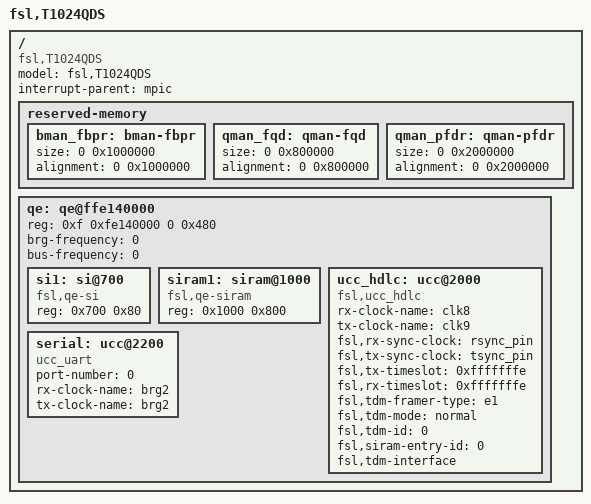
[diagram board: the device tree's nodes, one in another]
/*
 * T1024 QDS Device Tree Source
 *
 * Copyright 2014 Freescale Semiconductor Inc.
 *
 * Redistribution and use in source and binary forms, with or without
 * modification, are permitted provided that the following conditions are met:
 *     * Redistributions of source code must retain the above copyright
 *	 notice, this list of conditions and the following disclaimer.
 *     * Redistributions in binary form must reproduce the above copyright
 *	 notice, this list of conditions and the following disclaimer in the
 *	 documentation and/or other materials provided with the distribution.
 *     * Neither the name of Freescale Semiconductor nor the
 *	 names of its contributors may be used to endorse or promote products
 *	 derived from this software without specific prior written permission.
 *
 *
 * ALTERNATIVELY, this software may be distributed under the terms of the
 * GNU General Public License ("GPL") as published by the Free Software
 * Foundation, either version 2 of that License or (at your option) any
 * later version.
 *
 * THIS SOFTWARE IS PROVIDED BY Freescale Semiconductor "AS IS" AND ANY
 * EXPRESS OR IMPLIED WARRANTIES, INCLUDING, BUT NOT LIMITED TO, THE IMPLIED
 * WARRANTIES OF MERCHANTABILITY AND FITNESS FOR A PARTICULAR PURPOSE ARE
 * DISCLAIMED. IN NO EVENT SHALL Freescale Semiconductor BE LIABLE FOR ANY
 * DIRECT, INDIRECT, INCIDENTAL, SPECIAL, EXEMPLARY, OR CONSEQUENTIAL DAMAGES
 * (INCLUDING, BUT NOT LIMITED TO, PROCUREMENT OF SUBSTITUTE GOODS OR SERVICES;
 * LOSS OF USE, DATA, OR PROFITS; OR BUSINESS INTERRUPTION) HOWEVER CAUSED AND
 * ON ANY THEORY OF LIABILITY, WHETHER IN CONTRACT, STRICT LIABILITY, OR TORT
 * (INCLUDING NEGLIGENCE OR OTHERWISE) ARISING IN ANY WAY OUT OF THE USE OF THIS
 * SOFTWARE, EVEN IF ADVISED OF THE POSSIBILITY OF SUCH DAMAGE.
 */

/include/ "t102xsi-pre.dtsi"
/include/ "t102xqds.dtsi"

/ {
	model = "fsl,T1024QDS";
	compatible = "fsl,T1024QDS";
	#address-cells = <2>;
	#size-cells = <2>;
	interrupt-parent = <&mpic>;

	reserved-memory {
		#address-cells = <2>;
		#size-cells = <2>;
		ranges;

		bman_fbpr: bman-fbpr {
			size = <0 0x1000000>;
			alignment = <0 0x1000000>;
		};
		qman_fqd: qman-fqd {
			size = <0 0x800000>;
			alignment = <0 0x800000>;
		};
		qman_pfdr: qman-pfdr {
			size = <0 0x2000000>;
			alignment = <0 0x2000000>;
		};
	};

	qe: qe@ffe140000 {
		ranges = <0x0 0xf 0xfe140000 0x40000>;
		reg = <0xf 0xfe140000 0 0x480>;
		brg-frequency = <0>;
		bus-frequency = <0>;

		si1: si@700 {
			#address-cells = <1>;
			#size-cells = <0>;
			compatible = "fsl,qe-si";
			reg = <0x700 0x80>;
		};

		siram1: siram@1000 {
			#address-cells = <1>;
			#size-cells = <1>;
			compatible = "fsl,qe-siram";
			reg = <0x1000 0x800>;
		};

		ucc_hdlc: ucc@2000 {
			compatible = "fsl,ucc_hdlc";
			rx-clock-name = "clk8";
			tx-clock-name = "clk9";
			fsl,rx-sync-clock = "rsync_pin";
			fsl,tx-sync-clock = "tsync_pin";
			fsl,tx-timeslot = <0xfffffffe>;
			fsl,rx-timeslot = <0xfffffffe>;
			fsl,tdm-framer-type = "e1";
			fsl,tdm-mode = "normal";
			fsl,tdm-id = <0>;
			fsl,siram-entry-id = <0>;
			fsl,tdm-interface;
		};

		serial: ucc@2200 {
			device_type = "serial";
			compatible = "ucc_uart";
			port-number = <0>;
			rx-clock-name = "brg2";
			tx-clock-name = "brg2";
		};
	};
};

#include "t1024si-post.dtsi"
/include/ "qoriq-dpaa-res3.dtsi"
